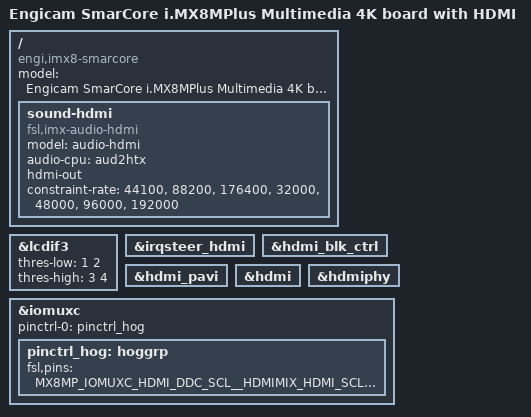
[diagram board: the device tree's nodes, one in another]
// SPDX-License-Identifier: (GPL-2.0+ OR MIT)
/*
 * Copyright 2022 Engicam
 */

/dts-v1/;

#include "imx8mp-smarcore-multimedia-4k.dts"

/ {
	model = "Engicam SmarCore i.MX8MPlus Multimedia 4K board with HDMI";
	compatible = "engi,imx8-smarcore", "fsl,imx8mp";
	
	sound-hdmi {
		compatible = "fsl,imx-audio-hdmi";
		model = "audio-hdmi";
		audio-cpu = <&aud2htx>;
		hdmi-out;
		constraint-rate = <44100>,
				<88200>,
				<176400>,
				<32000>,
				<48000>,
				<96000>,
				<192000>;
		status = "okay";
	};
	
};


&lcdif3 {
	status = "okay";

	thres-low  = <1 2>;             /* (FIFO * 1 / 2) */
	thres-high = <3 4>;             /* (FIFO * 3 / 4) */
};

&irqsteer_hdmi {
	status = "okay";
};

&hdmi_blk_ctrl {
	status = "okay";
};

&hdmi_pavi {
	status = "okay";
};

&hdmi {
	status = "okay";
};

&hdmiphy {
	status = "okay";
};

&iomuxc {
  	
	pinctrl-names = "default";
	pinctrl-0 = <&pinctrl_hog>;
	pinctrl_hog: hoggrp {
		fsl,pins = <
			MX8MP_IOMUXC_HDMI_DDC_SCL__HDMIMIX_HDMI_SCL	0x400001c3
			MX8MP_IOMUXC_HDMI_DDC_SDA__HDMIMIX_HDMI_SDA	0x400001c3
			MX8MP_IOMUXC_HDMI_HPD__HDMIMIX_HDMI_HPD		0x40000019
			MX8MP_IOMUXC_HDMI_CEC__HDMIMIX_HDMI_CEC		0x40000019
		>;
	};

};
